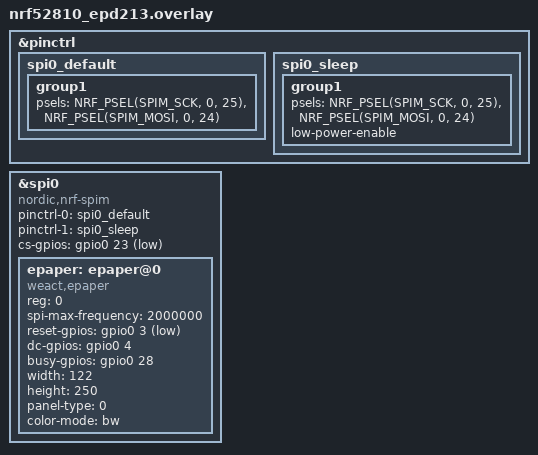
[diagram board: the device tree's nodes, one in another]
/*
 * Copyright (c) 2025 WeAct Studio
 * SPDX-License-Identifier: Apache-2.0
 *
 * nRF52810-DK + WeAct 2.13" E-Paper Display (122x250)
 */

&pinctrl {
	spi0_default: spi0_default {
		group1 {
			psels = <NRF_PSEL(SPIM_SCK, 0, 25)>,
				<NRF_PSEL(SPIM_MOSI, 0, 24)>;
		};
	};

	spi0_sleep: spi0_sleep {
		group1 {
			psels = <NRF_PSEL(SPIM_SCK, 0, 25)>,
				<NRF_PSEL(SPIM_MOSI, 0, 24)>;
			low-power-enable;
		};
	};
};

&spi0 {
	compatible = "nordic,nrf-spim";
	status = "okay";
	pinctrl-0 = <&spi0_default>;
	pinctrl-1 = <&spi0_sleep>;
	pinctrl-names = "default", "sleep";
	cs-gpios = <&gpio0 23 GPIO_ACTIVE_LOW>;

	epaper: epaper@0 {
		compatible = "weact,epaper";
		reg = <0>;
		spi-max-frequency = <2000000>;
		reset-gpios = <&gpio0 3 GPIO_ACTIVE_LOW>;
		dc-gpios = <&gpio0 4 GPIO_ACTIVE_HIGH>;
		busy-gpios = <&gpio0 28 GPIO_ACTIVE_HIGH>;
		width = <122>;
		height = <250>;
		panel-type = <0>; /* EPD213_219 */
		color-mode = "bw";
	};
};
